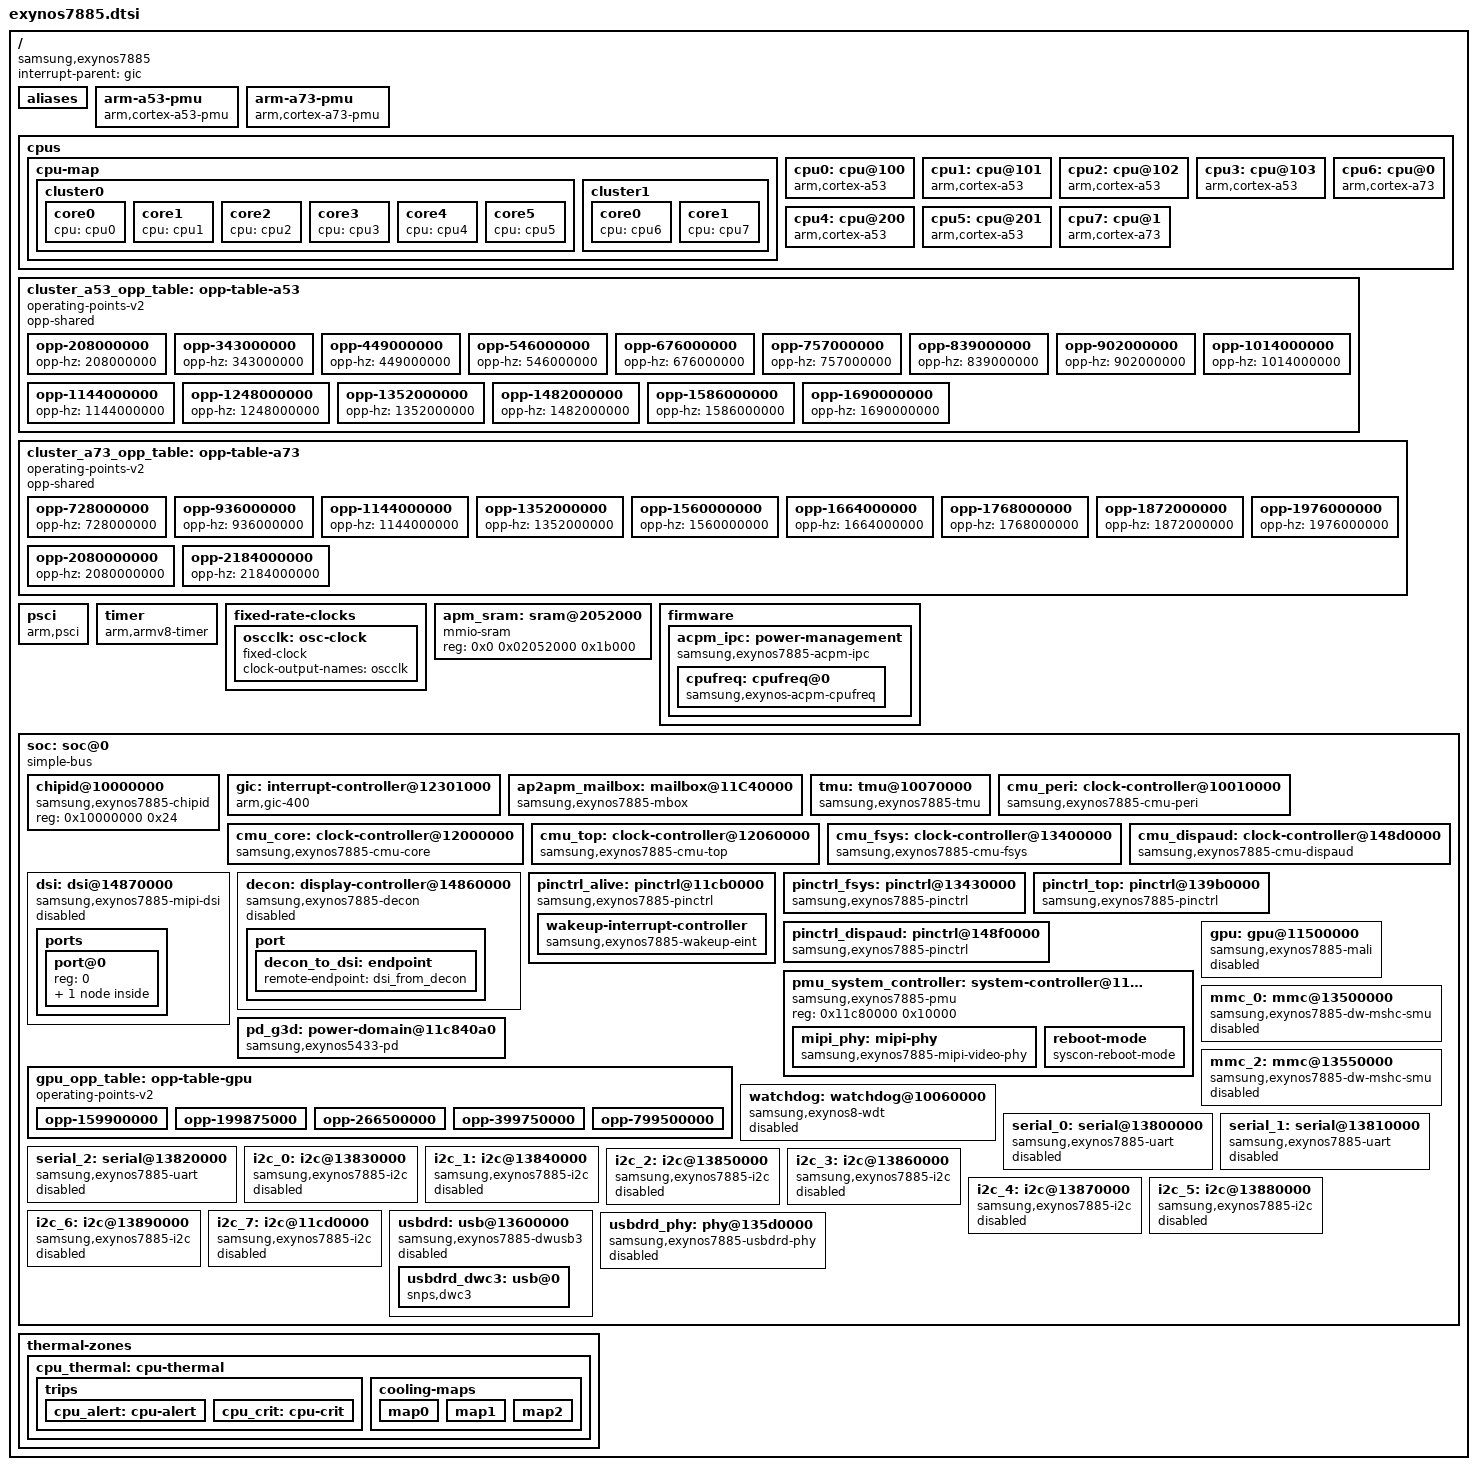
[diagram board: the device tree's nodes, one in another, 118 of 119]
// SPDX-License-Identifier: GPL-2.0
/*
 * Samsung Exynos7885 SoC device tree source
 *
 * Copyright (c) 2021 Samsung Electronics Co., Ltd.
 * Copyright (c) 2021 Dávid Virág
 */

#include <dt-bindings/clock/exynos7885.h>
#include <dt-bindings/interrupt-controller/arm-gic.h>
#include <dt-bindings/thermal/thermal.h>

/*
 * ACPM DVFS IDs for CPU clusters.
 * CPUCL0 (0x0B040002) = big cluster (cpu6-7, Cortex-A73, up to 2184 MHz)
 * CPUCL1 (0x0B040003) = little cluster (cpu0-5, Cortex-A53, up to 1690 MHz)
 * Frequencies from downstream exynos7885 device tree.
 */

/ {
	compatible = "samsung,exynos7885";
	#address-cells = <2>;
	#size-cells = <1>;

	interrupt-parent = <&gic>;

	aliases {
		pinctrl0 = &pinctrl_alive;
		pinctrl1 = &pinctrl_dispaud;
		pinctrl2 = &pinctrl_fsys;
		pinctrl3 = &pinctrl_top;
	};

	arm-a53-pmu {
		compatible = "arm,cortex-a53-pmu";
		interrupts = <GIC_SPI 96 IRQ_TYPE_LEVEL_HIGH>,
			     <GIC_SPI 97 IRQ_TYPE_LEVEL_HIGH>,
			     <GIC_SPI 98 IRQ_TYPE_LEVEL_HIGH>,
			     <GIC_SPI 99 IRQ_TYPE_LEVEL_HIGH>,
			     <GIC_SPI 218 IRQ_TYPE_LEVEL_HIGH>,
			     <GIC_SPI 219 IRQ_TYPE_LEVEL_HIGH>;
		interrupt-affinity = <&cpu0>,
				     <&cpu1>,
				     <&cpu2>,
				     <&cpu3>,
				     <&cpu4>,
				     <&cpu5>;
	};

	arm-a73-pmu {
		compatible = "arm,cortex-a73-pmu";
		interrupts = <GIC_SPI 82 IRQ_TYPE_LEVEL_HIGH>,
			     <GIC_SPI 83 IRQ_TYPE_LEVEL_HIGH>;
		interrupt-affinity = <&cpu6>,
				     <&cpu7>;
	};

	cpus {
		#address-cells = <1>;
		#size-cells = <0>;

		cpu-map {
			cluster0 {
				core0 {
					cpu = <&cpu0>;
				};

				core1 {
					cpu = <&cpu1>;
				};

				core2 {
					cpu = <&cpu2>;
				};

				core3 {
					cpu = <&cpu3>;
				};

				core4 {
					cpu = <&cpu4>;
				};

				core5 {
					cpu = <&cpu5>;
				};
			};

			cluster1 {
				core0 {
					cpu = <&cpu6>;
				};

				core1 {
					cpu = <&cpu7>;
				};
			};
		};

		cpu0: cpu@100 {
			device_type = "cpu";
			compatible = "arm,cortex-a53";
			reg = <0x100>;
			enable-method = "psci";
			operating-points-v2 = <&cluster_a53_opp_table>;
			samsung,acpm-dvfs-id = <0x0B040003>;
			#cooling-cells = <2>;
		};

		cpu1: cpu@101 {
			device_type = "cpu";
			compatible = "arm,cortex-a53";
			reg = <0x101>;
			enable-method = "psci";
			operating-points-v2 = <&cluster_a53_opp_table>;
			samsung,acpm-dvfs-id = <0x0B040003>;
			#cooling-cells = <2>;
		};

		cpu2: cpu@102 {
			device_type = "cpu";
			compatible = "arm,cortex-a53";
			reg = <0x102>;
			enable-method = "psci";
			operating-points-v2 = <&cluster_a53_opp_table>;
			samsung,acpm-dvfs-id = <0x0B040003>;
			#cooling-cells = <2>;
		};

		cpu3: cpu@103 {
			device_type = "cpu";
			compatible = "arm,cortex-a53";
			reg = <0x103>;
			enable-method = "psci";
			operating-points-v2 = <&cluster_a53_opp_table>;
			samsung,acpm-dvfs-id = <0x0B040003>;
			#cooling-cells = <2>;
		};

		cpu4: cpu@200 {
			device_type = "cpu";
			compatible = "arm,cortex-a53";
			reg = <0x200>;
			enable-method = "psci";
			operating-points-v2 = <&cluster_a53_opp_table>;
			samsung,acpm-dvfs-id = <0x0B040003>;
			#cooling-cells = <2>;
		};

		cpu5: cpu@201 {
			device_type = "cpu";
			compatible = "arm,cortex-a53";
			reg = <0x201>;
			enable-method = "psci";
			operating-points-v2 = <&cluster_a53_opp_table>;
			samsung,acpm-dvfs-id = <0x0B040003>;
			#cooling-cells = <2>;
		};

		cpu6: cpu@0 {
			device_type = "cpu";
			compatible = "arm,cortex-a73";
			reg = <0x0>;
			enable-method = "psci";
			operating-points-v2 = <&cluster_a73_opp_table>;
			samsung,acpm-dvfs-id = <0x0B040002>;
			#cooling-cells = <2>;
		};

		cpu7: cpu@1 {
			device_type = "cpu";
			compatible = "arm,cortex-a73";
			reg = <0x1>;
			enable-method = "psci";
			operating-points-v2 = <&cluster_a73_opp_table>;
			samsung,acpm-dvfs-id = <0x0B040002>;
			#cooling-cells = <2>;
		};
	};

	cluster_a53_opp_table: opp-table-a53 {
		compatible = "operating-points-v2";
		opp-shared;

		opp-208000000  { opp-hz = /bits/ 64 <208000000>; };
		opp-343000000  { opp-hz = /bits/ 64 <343000000>; };
		opp-449000000  { opp-hz = /bits/ 64 <449000000>; };
		opp-546000000  { opp-hz = /bits/ 64 <546000000>; };
		opp-676000000  { opp-hz = /bits/ 64 <676000000>; };
		opp-757000000  { opp-hz = /bits/ 64 <757000000>; };
		opp-839000000  { opp-hz = /bits/ 64 <839000000>; };
		opp-902000000  { opp-hz = /bits/ 64 <902000000>; };
		opp-1014000000 { opp-hz = /bits/ 64 <1014000000>; };
		opp-1144000000 { opp-hz = /bits/ 64 <1144000000>; };
		opp-1248000000 { opp-hz = /bits/ 64 <1248000000>; };
		opp-1352000000 { opp-hz = /bits/ 64 <1352000000>; };
		opp-1482000000 { opp-hz = /bits/ 64 <1482000000>; };
		opp-1586000000 { opp-hz = /bits/ 64 <1586000000>; };
		opp-1690000000 { opp-hz = /bits/ 64 <1690000000>; };
	};

	cluster_a73_opp_table: opp-table-a73 {
		compatible = "operating-points-v2";
		opp-shared;

		opp-728000000  { opp-hz = /bits/ 64 <728000000>; };
		opp-936000000  { opp-hz = /bits/ 64 <936000000>; };
		opp-1144000000 { opp-hz = /bits/ 64 <1144000000>; };
		opp-1352000000 { opp-hz = /bits/ 64 <1352000000>; };
		opp-1560000000 { opp-hz = /bits/ 64 <1560000000>; };
		opp-1664000000 { opp-hz = /bits/ 64 <1664000000>; };
		opp-1768000000 { opp-hz = /bits/ 64 <1768000000>; };
		opp-1872000000 { opp-hz = /bits/ 64 <1872000000>; };
		opp-1976000000 { opp-hz = /bits/ 64 <1976000000>; };
		opp-2080000000 { opp-hz = /bits/ 64 <2080000000>; };
		opp-2184000000 { opp-hz = /bits/ 64 <2184000000>; };
	};

	psci {
		compatible = "arm,psci";
		method = "smc";
		cpu_suspend = <0xc4000001>;
		cpu_off = <0x84000002>;
		cpu_on = <0xc4000003>;
	};

	timer {
		compatible = "arm,armv8-timer";
		/* Hypervisor Virtual Timer interrupt is not wired to GIC */
		interrupts = <GIC_PPI 13 (GIC_CPU_MASK_SIMPLE(8) | IRQ_TYPE_LEVEL_LOW)>,
			     <GIC_PPI 14 (GIC_CPU_MASK_SIMPLE(8) | IRQ_TYPE_LEVEL_LOW)>,
			     <GIC_PPI 11 (GIC_CPU_MASK_SIMPLE(8) | IRQ_TYPE_LEVEL_LOW)>,
			     <GIC_PPI 10 (GIC_CPU_MASK_SIMPLE(8) | IRQ_TYPE_LEVEL_LOW)>;
	};

	fixed-rate-clocks {
		oscclk: osc-clock {
			compatible = "fixed-clock";
			#clock-cells = <0>;
			clock-output-names = "oscclk";
		};
	};

	apm_sram: sram@2052000 {
		compatible = "mmio-sram";
		reg = <0x0 0x02052000 0x1b000>;
		#address-cells = <1>;
		#size-cells = <1>;
		ranges = <0x0 0x0 0x02052000 0x1b000>;
	};

	firmware {
		acpm_ipc: power-management {
			compatible = "samsung,exynos7885-acpm-ipc";
			#address-cells = <1>;
			#size-cells = <0>;
			mboxes = <&ap2apm_mailbox>;
			shmem = <&apm_sram>;

			cpufreq: cpufreq@0 {
				compatible = "samsung,exynos-acpm-cpufreq";
				reg = <0>;
				samsung,acpm-dvfs-channel = <0>;
			};
		};
	};

	soc: soc@0 {
		compatible = "simple-bus";
		#address-cells = <1>;
		#size-cells = <1>;
		ranges = <0x0 0x0 0x0 0x20000000>;

		chipid@10000000 {
			compatible = "samsung,exynos7885-chipid",
				     "samsung,exynos850-chipid";
			reg = <0x10000000 0x24>;
		};

		gic: interrupt-controller@12301000 {
			compatible = "arm,gic-400";
			#interrupt-cells = <3>;
			#address-cells = <0>;
			interrupt-controller;
			reg = <0x12301000 0x1000>,
			      <0x12302000 0x2000>,
			      <0x12304000 0x2000>,
			      <0x12306000 0x2000>;
			interrupts = <GIC_PPI 9 (GIC_CPU_MASK_SIMPLE(8) | IRQ_TYPE_LEVEL_HIGH)>;
		};

		ap2apm_mailbox: mailbox@11C40000 {
			compatible = "samsung,exynos7885-mbox";
			reg = <0x11C40000 0x1000>;
			clocks = <&cmu_top CLK_GOUT_APM_MAILBOX_APM_AP_PCLK>;
			clock-names = "pclk";
			interrupts = <GIC_SPI 22 IRQ_TYPE_LEVEL_HIGH 0>;
			#mbox-cells = <0>;
		};

		tmu: tmu@10070000 {
			compatible = "samsung,exynos7885-tmu";
			reg = <0x10070000 0x400>;
			interrupts = <GIC_SPI 231 IRQ_TYPE_LEVEL_HIGH>;
			clocks = <&cmu_peri CLK_GOUT_TMU_PCLK>;
			clock-names = "tmu_apbif";
			#thermal-sensor-cells = <0>;
		};

		cmu_peri: clock-controller@10010000 {
			compatible = "samsung,exynos7885-cmu-peri";
			reg = <0x10010000 0x8000>;
			#clock-cells = <1>;

			clocks = <&oscclk>,
				 <&cmu_top CLK_DOUT_PERI_BUS>,
				 <&cmu_top CLK_DOUT_PERI_SPI0>,
				 <&cmu_top CLK_DOUT_PERI_SPI1>,
				 <&cmu_top CLK_DOUT_PERI_UART0>,
				 <&cmu_top CLK_DOUT_PERI_UART1>,
				 <&cmu_top CLK_DOUT_PERI_UART2>,
				 <&cmu_top CLK_DOUT_PERI_USI0>,
				 <&cmu_top CLK_DOUT_PERI_USI1>,
				 <&cmu_top CLK_DOUT_PERI_USI2>;
			clock-names = "oscclk",
				      "dout_peri_bus",
				      "dout_peri_spi0",
				      "dout_peri_spi1",
				      "dout_peri_uart0",
				      "dout_peri_uart1",
				      "dout_peri_uart2",
				      "dout_peri_usi0",
				      "dout_peri_usi1",
				      "dout_peri_usi2";
		};

		cmu_core: clock-controller@12000000 {
			compatible = "samsung,exynos7885-cmu-core";
			reg = <0x12000000 0x8000>;
			#clock-cells = <1>;

			clocks = <&oscclk>,
				 <&cmu_top CLK_DOUT_CORE_BUS>,
				 <&cmu_top CLK_DOUT_CORE_CCI>,
				 <&cmu_top CLK_DOUT_CORE_G3D>;
			clock-names = "oscclk",
				      "dout_core_bus",
				      "dout_core_cci",
				      "dout_core_g3d";
		};

		cmu_top: clock-controller@12060000 {
			compatible = "samsung,exynos7885-cmu-top";
			reg = <0x12060000 0x8000>;
			#clock-cells = <1>;

			clocks = <&oscclk>;
			clock-names = "oscclk";
		};

		cmu_fsys: clock-controller@13400000 {
			compatible = "samsung,exynos7885-cmu-fsys";
			reg = <0x13400000 0x8000>;
			#clock-cells = <1>;

			clocks = <&oscclk>,
				 <&cmu_top CLK_DOUT_FSYS_BUS>,
				 <&cmu_top CLK_DOUT_FSYS_MMC_CARD>,
				 <&cmu_top CLK_DOUT_FSYS_MMC_EMBD>,
				 <&cmu_top CLK_DOUT_FSYS_MMC_SDIO>,
				 <&cmu_top CLK_DOUT_FSYS_USB30DRD>;
			clock-names = "oscclk",
				      "dout_fsys_bus",
				      "dout_fsys_mmc_card",
				      "dout_fsys_mmc_embd",
				      "dout_fsys_mmc_sdio",
				      "dout_fsys_usb30drd";
		};

		cmu_dispaud: clock-controller@148d0000 {
			compatible = "samsung,exynos7885-cmu-dispaud";
			reg = <0x148d0000 0x1000>;
			#clock-cells = <1>;

			clocks = <&oscclk>;
			clock-names = "oscclk";
		};

		dsi: dsi@14870000 {
			compatible = "samsung,exynos7885-mipi-dsi";
			reg = <0x14870000 0x100>;
			interrupts = <GIC_SPI 125 IRQ_TYPE_LEVEL_HIGH>;
			samsung,esc-clock-frequency = <20000000>;
			samsung,pll-clock-frequency = <26000000>;

			clocks = <&cmu_dispaud CLK_GOUT_DISPAUD_BUS_DPU>,
				 <&cmu_dispaud CLK_GOUT_DISPAUD_MUX_PLL>,
				 <&cmu_dispaud CLK_GOUT_DISPAUD_MUX_MIPIPHY_TXBYTECLKHS_USER>,
				 <&cmu_dispaud CLK_GOUT_DISPAUD_MUX_MIPIPHY_RXCLKESC0_USER>;
			clock-names = "bus", "pll", "byte", "esc";

			phys = <&mipi_phy 1>;
			phy-names = "dsim";

			status = "disabled";

			ports {
				#address-cells = <1>;
				#size-cells = <0>;

				port@0 {
					reg = <0>;

					dsi_from_decon: endpoint {
						remote-endpoint = <&decon_to_dsi>;
					};
				};
			};
		};

		decon: display-controller@14860000 {
			compatible = "samsung,exynos7885-decon";
			reg = <0x14860000 0x10000>,
			      <0x148B1000 0x1000>;	/* IDMA0 (DPP0/IDMA_G0) */
			interrupt-names = "fifo", "vsync", "lcd_sys";
			interrupts = <GIC_SPI 115 IRQ_TYPE_LEVEL_HIGH>,
				     <GIC_SPI 114 IRQ_TYPE_LEVEL_HIGH>,
				     <GIC_SPI 113 IRQ_TYPE_LEVEL_HIGH>;

			clocks = <&cmu_dispaud CLK_GOUT_DISPAUD_APB_DPU>,
				 <&cmu_dispaud CLK_GOUT_DISPAUD_BUS_DPU>,
				 <&cmu_dispaud CLK_GOUT_DISPAUD_DPU_DECON0>,
				 <&cmu_dispaud CLK_GOUT_DISPAUD_MUX_PLL>;
			clock-names = "pclk_decon0", "aclk_decon0",
				      "decon0_eclk", "decon0_vclk";

			status = "disabled";

			port {
				decon_to_dsi: endpoint {
					remote-endpoint = <&dsi_from_decon>;
				};
			};
		};

		pinctrl_alive: pinctrl@11cb0000 {
			compatible = "samsung,exynos7885-pinctrl";
			reg = <0x11cb0000 0x1000>;
			interrupts = <0 0 4>,
					<0 1 4>,
					<0 2 4>,
					<0 3 4>,
					<0 4 4>,
					<0 5 4>,
					<0 6 4>,
					<0 7 4>,
					<0 8 4>,
					<0 9 4>,
					<0 10 4>,
					<0 11 4>,
					<0 12 4>,
					<0 13 4>,
					<0 14 4>,
					<0 15 4>;

			wakeup-interrupt-controller {
				compatible = "samsung,exynos7885-wakeup-eint",
					     "samsung,exynos7-wakeup-eint";
				interrupt-parent = <&gic>;
				interrupts = <GIC_SPI 16 IRQ_TYPE_LEVEL_HIGH>;
			};
		};

		pinctrl_fsys: pinctrl@13430000 {
			compatible = "samsung,exynos7885-pinctrl";
			reg = <0x13430000 0x1000>;
			interrupts = <GIC_SPI 150 IRQ_TYPE_LEVEL_HIGH>;
		};

		pinctrl_top: pinctrl@139b0000 {
			compatible = "samsung,exynos7885-pinctrl";
			reg = <0x139b0000 0x1000>;
			interrupts = <GIC_SPI 266 IRQ_TYPE_LEVEL_HIGH>;
		};

		pinctrl_dispaud: pinctrl@148f0000 {
			compatible = "samsung,exynos7885-pinctrl";
			reg = <0x148f0000 0x1000>;
			interrupts = <GIC_SPI 130 IRQ_TYPE_LEVEL_HIGH>;
		};

		pmu_system_controller: system-controller@11c80000 {
			compatible = "samsung,exynos7885-pmu",
				     "samsung,exynos7-pmu", "syscon";
			reg = <0x11c80000 0x10000>;

			mipi_phy: mipi-phy {
				compatible = "samsung,exynos7885-mipi-video-phy";
				#phy-cells = <1>;
			};

			reboot-mode {
				compatible = "syscon-reboot-mode";
				offset = <0x0810>;
				mode-charge = <0x0a>;
				mode-fastboot = <0xfc>;
				mode-download = <0xfe>;
				mode-recovery = <0xff>;
			};
		};

		pd_g3d: power-domain@11c840a0 {
			compatible = "samsung,exynos5433-pd";
			reg = <0x11c840a0 0x20>;
			#power-domain-cells = <0>;
			label = "G3D";
		};

		gpu: gpu@11500000 {
			compatible = "samsung,exynos7885-mali", "arm,mali-bifrost";
			reg = <0x11500000 0x5000>;
			interrupts = <GIC_SPI 159 IRQ_TYPE_LEVEL_HIGH>,
				     <GIC_SPI 160 IRQ_TYPE_LEVEL_HIGH>,
				     <GIC_SPI 158 IRQ_TYPE_LEVEL_HIGH>;
			interrupt-names = "job", "mmu", "gpu";
			clocks = <&cmu_top CLK_DOUT_CORE_G3D>;
			power-domains = <&pd_g3d>;
			operating-points-v2 = <&gpu_opp_table>;
			#cooling-cells = <2>;
			status = "disabled";
		};

		/*
		 * Frequency-only OPPs: vdd_g3d (PMIC buck) is ACPM-owned and not
		 * host-settable, so no opp-microvolt - the rail stays at the boot
		 * voltage (which supports the 799.5 MHz top point) while devfreq
		 * scales only the clock divider.  Rates are 799.5 MHz / 1..5.
		 * opp-microwatt are rough estimates (voltage fixed, so dynamic
		 * power scales ~linearly with frequency); they feed the Energy
		 * Model used by the GPU thermal cooling device.
		 */
		gpu_opp_table: opp-table-gpu {
			compatible = "operating-points-v2";

			opp-159900000 {
				opp-hz = /bits/ 64 <159900000>;
				opp-microwatt = <240000>;
			};
			opp-199875000 {
				opp-hz = /bits/ 64 <199875000>;
				opp-microwatt = <300000>;
			};
			opp-266500000 {
				opp-hz = /bits/ 64 <266500000>;
				opp-microwatt = <400000>;
			};
			opp-399750000 {
				opp-hz = /bits/ 64 <399750000>;
				opp-microwatt = <600000>;
			};
			opp-799500000 {
				opp-hz = /bits/ 64 <799500000>;
				opp-microwatt = <1200000>;
			};
		};

		watchdog: watchdog@10060000 {
			compatible = "samsung,exynos8-wdt";
			reg = <0x10060000 0x100>;
			interrupts = <GIC_SPI 233 IRQ_TYPE_LEVEL_HIGH>;
			clocks = <&cmu_peri CLK_GOUT_WDT1_PCLK>, <&oscclk>;
			clock-names = "watchdog", "watchdog_src";
			samsung,syscon-phandle = <&pmu_system_controller>;
			timeout-sec = <30>;
			status = "disabled";
		};

		mmc_0: mmc@13500000 {
			compatible = "samsung,exynos7885-dw-mshc-smu",
				     "samsung,exynos7-dw-mshc-smu";
			reg = <0x13500000 0x2000>;
			interrupts = <GIC_SPI 146 IRQ_TYPE_LEVEL_HIGH>;
			#address-cells = <1>;
			#size-cells = <0>;
			clocks = <&cmu_fsys CLK_GOUT_MMC_EMBD_ACLK>,
				 <&cmu_fsys CLK_GOUT_MMC_EMBD_SDCLKIN>;
			clock-names = "biu", "ciu";
			fifo-depth = <0x40>;

			status = "disabled";
		};

		mmc_2: mmc@13550000 {
			compatible = "samsung,exynos7885-dw-mshc-smu",
				     "samsung,exynos7-dw-mshc-smu";
			reg = <0x13550000 0x2000>;
			interrupts = <GIC_SPI 147 IRQ_TYPE_LEVEL_HIGH>;
			#address-cells = <1>;
			#size-cells = <0>;
			clocks = <&cmu_fsys CLK_GOUT_MMC_CARD_ACLK>,
				 <&cmu_fsys CLK_GOUT_MMC_CARD_SDCLKIN>;
			clock-names = "biu", "ciu";
			fifo-depth = <0x40>;
			status = "disabled";
		};

		serial_0: serial@13800000 {
			compatible = "samsung,exynos7885-uart",
				     "samsung,exynos5433-uart";
			reg = <0x13800000 0x100>;
			interrupts = <GIC_SPI 246 IRQ_TYPE_LEVEL_HIGH>;
			pinctrl-names = "default";
			pinctrl-0 = <&uart0_bus>;
			clocks = <&cmu_peri CLK_GOUT_UART0_PCLK>,
				 <&cmu_peri CLK_GOUT_UART0_EXT_UCLK>;
			clock-names = "uart", "clk_uart_baud0";
			samsung,uart-fifosize = <64>;

			status = "disabled";
		};

		serial_1: serial@13810000 {
			compatible = "samsung,exynos7885-uart",
				     "samsung,exynos5433-uart";
			reg = <0x13810000 0x100>;
			interrupts = <GIC_SPI 247 IRQ_TYPE_LEVEL_HIGH>;
			pinctrl-names = "default";
			pinctrl-0 = <&uart1_bus>;
			clocks = <&cmu_peri CLK_GOUT_UART1_PCLK>,
				 <&cmu_peri CLK_GOUT_UART1_EXT_UCLK>;
			clock-names = "uart", "clk_uart_baud0";
			samsung,uart-fifosize = <256>;

			status = "disabled";
		};

		serial_2: serial@13820000 {
			compatible = "samsung,exynos7885-uart",
				     "samsung,exynos5433-uart";
			reg = <0x13820000 0x100>;
			interrupts = <GIC_SPI 279 IRQ_TYPE_LEVEL_HIGH>;
			pinctrl-names = "default";
			pinctrl-0 = <&uart2_bus>;
			clocks = <&cmu_peri CLK_GOUT_UART2_PCLK>,
				 <&cmu_peri CLK_GOUT_UART2_EXT_UCLK>;
			clock-names = "uart", "clk_uart_baud0";
			samsung,uart-fifosize = <256>;

			status = "disabled";
		};

		i2c_0: i2c@13830000 {
			compatible = "samsung,exynos7885-i2c",
				     "samsung,s3c2440-i2c";
			reg = <0x13830000 0x100>;
			interrupts = <GIC_SPI 248 IRQ_TYPE_LEVEL_HIGH>;
			#address-cells = <1>;
			#size-cells = <0>;
			pinctrl-names = "default";
			pinctrl-0 = <&i2c0_bus>;
			clocks = <&cmu_peri CLK_GOUT_I2C0_PCLK>;
			clock-names = "i2c";

			status = "disabled";
		};

		i2c_1: i2c@13840000 {
			compatible = "samsung,exynos7885-i2c",
				     "samsung,s3c2440-i2c";
			reg = <0x13840000 0x100>;
			interrupts = <GIC_SPI 249 IRQ_TYPE_LEVEL_HIGH>;
			#address-cells = <1>;
			#size-cells = <0>;
			pinctrl-names = "default";
			pinctrl-0 = <&i2c1_bus>;
			clocks = <&cmu_peri CLK_GOUT_I2C1_PCLK>;
			clock-names = "i2c";

			status = "disabled";
		};

		i2c_2: i2c@13850000 {
			compatible = "samsung,exynos7885-i2c",
				     "samsung,s3c2440-i2c";
			reg = <0x13850000 0x100>;
			interrupts = <GIC_SPI 250 IRQ_TYPE_LEVEL_HIGH>;
			#address-cells = <1>;
			#size-cells = <0>;
			pinctrl-names = "default";
			pinctrl-0 = <&i2c2_bus>;
			clocks = <&cmu_peri CLK_GOUT_I2C2_PCLK>;
			clock-names = "i2c";

			status = "disabled";
		};

		i2c_3: i2c@13860000 {
			compatible = "samsung,exynos7885-i2c",
				     "samsung,s3c2440-i2c";
			reg = <0x13860000 0x100>;
			interrupts = <GIC_SPI 251 IRQ_TYPE_LEVEL_HIGH>;
			#address-cells = <1>;
			#size-cells = <0>;
			pinctrl-names = "default";
			pinctrl-0 = <&i2c3_bus>;
			clocks = <&cmu_peri CLK_GOUT_I2C3_PCLK>;
			clock-names = "i2c";

			status = "disabled";
		};

		i2c_4: i2c@13870000 {
			compatible = "samsung,exynos7885-i2c",
				     "samsung,s3c2440-i2c";
			reg = <0x13870000 0x100>;
			interrupts = <GIC_SPI 252 IRQ_TYPE_LEVEL_HIGH>;
			#address-cells = <1>;
			#size-cells = <0>;
			pinctrl-names = "default";
			pinctrl-0 = <&i2c4_bus>;
			clocks = <&cmu_peri CLK_GOUT_I2C4_PCLK>;
			clock-names = "i2c";

			status = "disabled";
		};

		i2c_5: i2c@13880000 {
			compatible = "samsung,exynos7885-i2c",
				     "samsung,s3c2440-i2c";
			reg = <0x13880000 0x100>;
			interrupts = <GIC_SPI 253 IRQ_TYPE_LEVEL_HIGH>;
			#address-cells = <1>;
			#size-cells = <0>;
			pinctrl-names = "default";
			pinctrl-0 = <&i2c5_bus>;
			clocks = <&cmu_peri CLK_GOUT_I2C5_PCLK>;
			clock-names = "i2c";

			status = "disabled";
		};

		i2c_6: i2c@13890000 {
			compatible = "samsung,exynos7885-i2c",
				     "samsung,s3c2440-i2c";
			reg = <0x13890000 0x100>;
			interrupts = <GIC_SPI 254 IRQ_TYPE_LEVEL_HIGH>;
			#address-cells = <1>;
			#size-cells = <0>;
			pinctrl-names = "default";
			pinctrl-0 = <&i2c6_bus>;
			clocks = <&cmu_peri CLK_GOUT_I2C6_PCLK>;
			clock-names = "i2c";

			status = "disabled";
		};

		i2c_7: i2c@11cd0000 {
			compatible = "samsung,exynos7885-i2c",
				     "samsung,s3c2440-i2c";
			reg = <0x11cd0000 0x100>;
			interrupts = <GIC_SPI 255 IRQ_TYPE_LEVEL_HIGH>;
			#address-cells = <1>;
			#size-cells = <0>;
			pinctrl-names = "default";
			pinctrl-0 = <&i2c7_bus>;
			clocks = <&cmu_peri CLK_GOUT_I2C7_PCLK>;
			clock-names = "i2c";

			status = "disabled";
		};

		usbdrd: usb@13600000 {
			compatible = "samsung,exynos7885-dwusb3";
			ranges = <0x0 0x13600000 0x10000>;
			clocks = <&cmu_fsys CLK_FSYS_USB30DRD_BUS_CLK_EARLY>,
				 <&cmu_fsys CLK_FSYS_USB30DRD_REF_CLK>;
			clock-names = "bus_early", "ref";
			#address-cells = <1>;
			#size-cells = <1>;
			status = "disabled";

			usbdrd_dwc3: usb@0 {
				compatible = "snps,dwc3";
				reg = <0x0 0x10000>;
				interrupts = <GIC_SPI 135 IRQ_TYPE_LEVEL_HIGH>;
				phys = <&usbdrd_phy 0>;
				phy-names = "usb2-phy";
				/*
				 * SoC in theory supports SS but no device has it.
				 * Actual capabilities unknown.
				 */
				maximum-speed = "high-speed";
				/*
				 * Keep the USB2 PHY clock running. This SoC's
				 * USB2 PHY has no free-running clock, but the
				 * controller defaults to assuming one exists
				 * (GUSB2PHYCFG.U2_FREECLK_EXISTS=1) and lets the
				 * PHY clock stop; combined with PHY auto-suspend,
				 * ep0 config commands then intermittently time
				 * out at gadget start ("failed to enable ep0out").
				 * Clear both: no free clock (like exynos2200) and
				 * no auto-suspend (like gs101, same PHY IP).
				 */
				snps,dis-u2-freeclk-exists-quirk;
				snps,dis_u2_susphy_quirk;
				snps,usb2-gadget-lpm-disable;
			};
		};

		usbdrd_phy: phy@135d0000 {
			compatible = "samsung,exynos7885-usbdrd-phy";
			reg = <0x135d0000 0x100>;
			clocks = <&cmu_fsys CLK_FSYS_USB30DRD_ACLK_20PHYCTRL>,
				 <&cmu_fsys CLK_FSYS_USB20PHY_CLKCORE>;
			clock-names = "phy", "ref";
			samsung,pmu-syscon = <&pmu_system_controller>;
			#phy-cells = <1>;
			status = "disabled";
		};
	};

	thermal-zones {
		cpu_thermal: cpu-thermal {
			polling-delay-passive = <1000>;
			polling-delay = <1000>;
			thermal-sensors = <&tmu>;

			trips {
				cpu_alert: cpu-alert {
					temperature = <95000>;
					hysteresis = <5000>;
					type = "passive";
				};

				cpu_crit: cpu-crit {
					temperature = <115000>;
					hysteresis = <0>;
					type = "critical";
				};
			};

			cooling-maps {
				map0 {
					trip = <&cpu_alert>;
					cooling-device = <&cpu0 THERMAL_NO_LIMIT THERMAL_NO_LIMIT>;
				};
				map1 {
					trip = <&cpu_alert>;
					cooling-device = <&cpu6 THERMAL_NO_LIMIT THERMAL_NO_LIMIT>;
				};

				/*
				 * Only one TMU sensor is modelled in mainline, and
				 * the thermal-OF core binds a sensor to a single
				 * zone, so the GPU is throttled (devfreq cooling)
				 * off this same SoC zone rather than a dedicated
				 * gpu-thermal zone.
				 */
				map2 {
					trip = <&cpu_alert>;
					cooling-device = <&gpu THERMAL_NO_LIMIT THERMAL_NO_LIMIT>;
				};
			};
		};
	};
};

#include "exynos7885-pinctrl.dtsi"
#include "arm/samsung/exynos-syscon-restart.dtsi"
